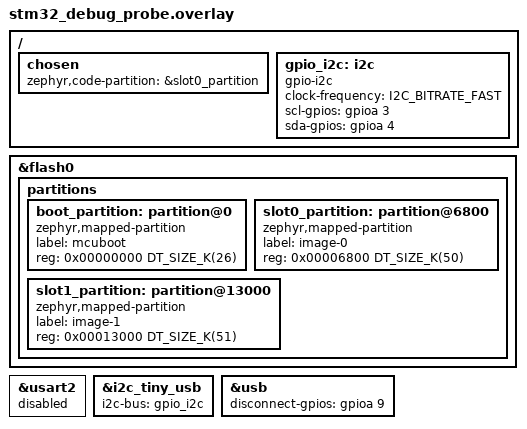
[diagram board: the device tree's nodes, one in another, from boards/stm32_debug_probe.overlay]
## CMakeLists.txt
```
# SPDX-FileCopyrightText: 2026 Muhammad Waleed Badar
# SPDX-License-Identifier: Apache-2.0

cmake_minimum_required(VERSION 3.20.0)

# The board overlays select the bus of the i2c-tiny-usb node of app.overlay,
# which Zephyr only uses for boards without an overlay of their own. Sysbuild
# builds get the same overlays from sysbuild.cmake. Twister passes the board
# with its revision and qualifiers, e.g. stm32f3_disco@B/stm32f303xc.
if(BOARD AND NOT DTC_OVERLAY_FILE)
  string(REGEX MATCH "^[^@/]+" board_name ${BOARD})
  set(board_overlay ${CMAKE_CURRENT_SOURCE_DIR}/boards/${board_name}.overlay)
  if(EXISTS ${board_overlay})
    set(DTC_OVERLAY_FILE "${CMAKE_CURRENT_SOURCE_DIR}/app.overlay;${board_overlay}")
  endif()
endif()

find_package(Zephyr REQUIRED HINTS $ENV{ZEPHYR_BASE})
project(i2c_tiny_usb_bridge)

target_sources(app PRIVATE src/main.c)
target_sources_ifdef(CONFIG_APP_USBD_WINUSB app PRIVATE src/msosv2.c)
target_sources_ifdef(CONFIG_APP_DFU app PRIVATE src/dfu.c)

if(CONFIG_APP_DFU)
  math(EXPR usbd_vid "${CONFIG_APP_USBD_VID}")
  math(EXPR usbd_pid "${CONFIG_APP_USBD_PID}")
endif()

if(CONFIG_APP_DFU AND usbd_vid EQUAL 1027 AND usbd_pid EQUAL 50737) # 0403:c631
  message(WARNING "The Linux i2c-tiny-usb driver binds to all interfaces of the USB IDs "
    "of the original i2c-tiny-usb adapter and also creates an I2C adapter for the DFU "
    "interface. Use other USB IDs for DFU support.")
endif()
```

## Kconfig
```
# SPDX-FileCopyrightText: 2026 Muhammad Waleed Badar
# SPDX-FileCopyrightText: Copyright (c) 2024-2026 Henrik Brix Andersen <henrik@brixandersen.dk>
# SPDX-License-Identifier: Apache-2.0

mainmenu "i2c-tiny-usb bridge"

menu "i2c-tiny-usb bridge"

module = APP
module-str = i2c-tiny-usb bridge
source "subsys/logging/Kconfig.template.log_config"

config APP_BOOT_BANNER
	bool "Boot banner"
	default y if BOOT_BANNER
	select PRINTK
	help
	  Print the firmware version during boot up.

config APP_USBD_MANUFACTURER
	string "USB device manufacturer string"
	default "zephyr-i2c-tiny-usb-bridge"

config APP_USBD_PRODUCT
	string "USB device product string"
	default "i2c-tiny-usb bridge"

config APP_USBD_VID
	hex "USB vendor ID"
	default 0x1209
	help
	  Defaults to the pid.codes test IDs 0x1209:0x0001, which are only
	  meant for testing and private use. Set your own IDs before
	  distributing a device: open source projects can get a product ID
	  under the vendor ID 0x1209 from pid.codes. The udev rules in the
	  repository bind the Linux i2c-tiny-usb driver to the IDs.

config APP_USBD_PID
	hex "USB product ID"
	default 0x0001

config APP_USBD_SELF_POWERED
	bool "USB device is self-powered"

config APP_USBD_MAX_POWER
	int "USB device maximum power"
	default 50
	range 0 250
	help
	  Maximum current draw from the bus in milliampere (mA) divided by 2.
	  A value of 50 results in a maximum current draw value of 100 mA.

config APP_USBD_WINUSB
	bool "Microsoft OS 2.0 descriptors for WinUSB"
	default y
	help
	  Report Microsoft OS 2.0 descriptors, so that Windows 8.1 and newer
	  install the WinUSB driver automatically. libusb based tools can then
	  access the device without a driver installation.

config APP_USBD_WINUSB_VENDOR_CODE
	hex "Microsoft OS 2.0 descriptor vendor code"
	default 0x20
	range 0x08 0xff
	depends on APP_USBD_WINUSB
	help
	  bRequest of the vendor request that reads the Microsoft OS 2.0
	  descriptor set. It must not collide with the i2c-tiny-usb commands
	  0 to 7.

menuconfig APP_DFU
	bool "USB Device Firmware Upgrade (DFU) support"
	default y
	depends on BOOTLOADER_MCUBOOT
	depends on $(dt_nodelabel_enabled,slot1_partition)
	select FLASH
	select FLASH_MAP
	select STREAM_FLASH
	select IMG_MANAGER
	select IMG_ERASE_PROGRESSIVELY
	select USBD_DFU
	select USBD_DFU_FLASH
	select REBOOT
	help
	  Add a DFU runtime interface. dfu-util switches the device into DFU
	  mode, downloads a signed image into the slot-1 partition, and the
	  device reboots into MCUboot, which swaps the images.

if APP_DFU

configdefault USBD_DFU_FLASH_SLOT0
	default n

configdefault USBD_DFU_FLASH_SLOT1
	default y

config APP_USBD_DFU_VID
	hex "USB vendor ID in DFU mode"
	default APP_USBD_VID

config APP_USBD_DFU_PID
	hex "USB product ID in DFU mode"
	default APP_USBD_PID

config APP_DFU_REBOOT_DELAY
	int "Reboot delay"
	default 100
	range 0 60000
	help
	  Delay in milliseconds between the completion of a DFU download and
	  the reboot into MCUboot.

endif # APP_DFU

endmenu

source "Kconfig.zephyr"
```

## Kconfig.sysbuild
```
# SPDX-FileCopyrightText: 2026 Muhammad Waleed Badar
# SPDX-FileCopyrightText: Copyright (c) 2024-2026 Henrik Brix Andersen <henrik@brixandersen.dk>
# SPDX-License-Identifier: Apache-2.0

# MCUboot with signature checking does not fit next to two image slots in the
# 128 KiB flash and 20 KiB RAM of the STM32F103. Images are still verified
# against their SHA-256 hash.
choice BOOT_SIGNATURE_TYPE
	default BOOT_SIGNATURE_TYPE_NONE if BOARD = "stm32_debug_probe"
endchoice

source "share/sysbuild/Kconfig"
```

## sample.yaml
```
# SPDX-FileCopyrightText: 2026 Muhammad Waleed Badar
# SPDX-FileCopyrightText: Copyright (c) 2024-2026 Henrik Brix Andersen <henrik@brixandersen.dk>
# SPDX-License-Identifier: Apache-2.0

sample:
  description: i2c-tiny-usb compatible USB to I2C bridge firmware
  name: i2c-tiny-usb bridge
common:
  tags:
    - i2c
    - usb
  depends_on:
    - usbd
tests:
  app.i2c_tiny_usb:
    platform_allow:
      - stm32f3_disco
    integration_platforms:
      - stm32f3_disco
  app.i2c_tiny_usb.debug:
    platform_allow:
      - stm32f3_disco
    integration_platforms:
      - stm32f3_disco
    extra_args:
      - FILE_SUFFIX=debug
    harness: console
    harness_config:
      type: one_line
      regex:
        - "i2c-tiny-usb bridge ready"
  app.i2c_tiny_usb.arduino:
    filter: dt_nodelabel_enabled("arduino_i2c") and dt_nodelabel_enabled("zephyr_udc0")
    platform_allow:
      - frdm_k64f
      - nrf52840dk/nrf52840
      - nucleo_f413zh
    integration_platforms:
      - frdm_k64f
      - nrf52840dk/nrf52840
      - nucleo_f413zh
    extra_args:
      - EXTRA_DTC_OVERLAY_FILE=overlays/arduino_i2c.overlay
  app.i2c_tiny_usb.dfu:
    sysbuild: true
    platform_allow:
      - stm32f3_disco
    integration_platforms:
      - stm32f3_disco
  app.i2c_tiny_usb.hil:
    # Runs on a bridge attached to the host running twister
    platform_allow:
      - stm32f3_disco
    extra_args:
      - FILE_SUFFIX=debug
    harness: pytest
    harness_config:
      fixture: i2c_tiny_usb_host
      pytest_root:
        - "pytest/test_bridge.py"
      pytest_args:
        # LSM303DLHC magnetometer identification registers, revision B
        - "--target=0x1e:0x0a:0x48"
        - "--target=0x1e:0x0b:0x34"
        - "--target=0x1e:0x0c:0x33"
        - "--absent=0x10"
```

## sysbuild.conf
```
# SPDX-FileCopyrightText: 2026 Muhammad Waleed Badar
# SPDX-License-Identifier: Apache-2.0

# Used with --sysbuild: MCUboot with USB DFU support in the application
SB_CONFIG_BOOTLOADER_MCUBOOT=y
```

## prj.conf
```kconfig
CONFIG_USB_DEVICE_STACK_NEXT=y
CONFIG_I2C=y

# Release configuration, see prj_debug.conf for logging
CONFIG_LOG=n
CONFIG_BOOT_BANNER=n
CONFIG_PRINTK=n
```

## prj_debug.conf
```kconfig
# SPDX-FileCopyrightText: 2026 Muhammad Waleed Badar
# SPDX-FileCopyrightText: Copyright (c) 2024-2026 Henrik Brix Andersen <henrik@brixandersen.dk>
# SPDX-License-Identifier: Apache-2.0

CONFIG_USB_DEVICE_STACK_NEXT=y
CONFIG_I2C=y

# Logging configuration
CONFIG_LOG=y
CONFIG_UDC_DRIVER_LOG_LEVEL_WRN=y
CONFIG_USBD_LOG_LEVEL_WRN=y
CONFIG_USBD_I2C_TINY_USB_LOG_LEVEL_DBG=y
CONFIG_APP_LOG_LEVEL_DBG=y
```

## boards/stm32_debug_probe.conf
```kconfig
CONFIG_SERIAL=n
CONFIG_I2C_GPIO=y
```

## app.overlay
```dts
/*
 * SPDX-FileCopyrightText: 2026 Muhammad Waleed Badar
 *
 * SPDX-License-Identifier: Apache-2.0
 */

/*
 * Bridges the zephyr_i2c bus by default, board and extra overlays select a
 * different bus through the i2c_tiny_usb label
 */
/ {
	i2c_tiny_usb: i2c-tiny-usb {
		compatible = "i2c-tiny-usb";
	};
};
```

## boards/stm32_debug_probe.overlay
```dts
/*
 * SPDX-FileCopyrightText: 2026 Muhammad Waleed Badar
 *
 * SPDX-License-Identifier: Apache-2.0
 */

#include <zephyr/dt-bindings/i2c/i2c.h>

/*
 * The bus is bit-banged on the J2 header, SCL on PA3 and SDA on PA4. PA3 and
 * PA4 are tied to PA5 and PA7 on the board, which are left as inputs.
 *
 * The STM32F1 has no pull-ups on open-drain outputs: the bus needs external
 * pull-ups to 3.3 V (4.7 kOhm), unless the target board provides them.
 */
/ {
	chosen {
		/delete-property/ zephyr,console;
		/delete-property/ zephyr,shell-uart;
		zephyr,code-partition = &slot0_partition;
	};

	gpio_i2c: i2c {
		compatible = "gpio-i2c";
		clock-frequency = <I2C_BITRATE_FAST>;
		scl-gpios = <&gpioa 3 GPIO_OPEN_DRAIN>;
		sda-gpios = <&gpioa 4 GPIO_OPEN_DRAIN>;
		#address-cells = <1>;
		#size-cells = <0>;
	};
};

/*
 * MCUboot flash layout for USB DFU. MCUboot without image signature checking
 * fits in 26 KiB. The secondary slot is one 1 KiB page larger than the
 * primary slot, as required by MCUboot's swap using offset mode.
 */
&flash0 {
	partitions {
		#address-cells = <1>;
		#size-cells = <1>;
		ranges;

		boot_partition: partition@0 {
			compatible = "zephyr,mapped-partition";
			label = "mcuboot";
			reg = <0x00000000 DT_SIZE_K(26)>;
		};

		slot0_partition: partition@6800 {
			compatible = "zephyr,mapped-partition";
			label = "image-0";
			reg = <0x00006800 DT_SIZE_K(50)>;
		};

		slot1_partition: partition@13000 {
			compatible = "zephyr,mapped-partition";
			label = "image-1";
			reg = <0x00013000 DT_SIZE_K(51)>;
		};
	};
};

/* PA3 is the USART2 RX pin, the console stays on RTT */
&usart2 {
	status = "disabled";
};

&i2c_tiny_usb {
	i2c-bus = <&gpio_i2c>;
};

&usb {
	disconnect-gpios = <&gpioa 9 GPIO_ACTIVE_HIGH>;
};
```

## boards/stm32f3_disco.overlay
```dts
/*
 * SPDX-FileCopyrightText: 2026 Muhammad Waleed Badar
 *
 * SPDX-License-Identifier: Apache-2.0
 */

/*
 * I2C1 on PB6 (SCL) and PB7 (SDA), shared with the on-board LSM303
 * accelerometer (0x19) and magnetometer (0x1e). The board enumerates through
 * the USB USER connector.
 */

&i2c_tiny_usb {
	i2c-bus = <&i2c1>;
};
```

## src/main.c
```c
/*
 * SPDX-FileCopyrightText: 2026 Muhammad Waleed Badar
 * SPDX-FileCopyrightText: Copyright (c) 2024-2026 Henrik Brix Andersen <henrik@brixandersen.dk>
 *
 * SPDX-License-Identifier: Apache-2.0
 */

#include <zephyr/app_version.h>
#include <zephyr/device.h>
#include <zephyr/sys/printk.h>
#include <zephyr/usb/usbd.h>

#include <zephyr/logging/log.h>
LOG_MODULE_REGISTER(main, CONFIG_APP_LOG_LEVEL);

#include "bridge.h"

BUILD_ASSERT(DT_HAS_COMPAT_STATUS_OKAY(i2c_tiny_usb),
	     "Add an i2c-tiny-usb devicetree node selecting the I2C bus to bridge");

#if defined(APP_BUILD_VERSION) && !IS_EMPTY(APP_BUILD_VERSION)
#define BANNER_VERSION APP_VERSION_STRING " (" STRINGIFY(APP_BUILD_VERSION) ")"
#else
#define BANNER_VERSION APP_VERSION_STRING
#endif

/* The Linux i2c-tiny-usb driver reports bcdDevice as the firmware version */
#define BRIDGE_BCD_DEVICE                                                                  \
	(USB_DEC_TO_BCD(APP_VERSION_MAJOR) << 8 | USB_DEC_TO_BCD(APP_VERSION_MINOR))

USBD_DEVICE_DEFINE(bridge_usbd, DEVICE_DT_GET(DT_NODELABEL(zephyr_udc0)), CONFIG_APP_USBD_VID,
		   CONFIG_APP_USBD_PID);

USBD_DESC_LANG_DEFINE(bridge_lang);
USBD_DESC_MANUFACTURER_DEFINE(bridge_mfr, CONFIG_APP_USBD_MANUFACTURER);
USBD_DESC_PRODUCT_DEFINE(bridge_product, CONFIG_APP_USBD_PRODUCT);
#ifdef CONFIG_HWINFO_HAS_DRIVER
/* Unique per device, lets the host tell several bridges apart */
USBD_DESC_SERIAL_NUMBER_DEFINE(bridge_sn);
#endif
USBD_DESC_CONFIG_DEFINE(fs_cfg_desc, "FS Configuration");
USBD_DESC_CONFIG_DEFINE(hs_cfg_desc, "HS Configuration");

#define BRIDGE_CFG_ATTRIB (IS_ENABLED(CONFIG_APP_USBD_SELF_POWERED) ? USB_SCD_SELF_POWERED : 0)

USBD_CONFIGURATION_DEFINE(fs_config, BRIDGE_CFG_ATTRIB, CONFIG_APP_USBD_MAX_POWER, &fs_cfg_desc);
USBD_CONFIGURATION_DEFINE(hs_config, BRIDGE_CFG_ATTRIB, CONFIG_APP_USBD_MAX_POWER, &hs_cfg_desc);

static void msg_cb(struct usbd_context *const usbd_ctx, const struct usbd_msg *const msg)
{
	LOG_INF("USBD message: %s", usbd_msg_type_string(msg->type));

	if (IS_ENABLED(CONFIG_APP_DFU) && msg->type == USBD_MSG_DFU_APP_DETACH) {
		bridge_dfu_switch(usbd_ctx);
		return;
	}

	if (!usbd_can_detect_vbus(usbd_ctx)) {
		return;
	}

	if (msg->type == USBD_MSG_VBUS_READY && usbd_enable(usbd_ctx) != 0) {
		LOG_ERR("Failed to enable device support");
	}

	if (msg->type == USBD_MSG_VBUS_REMOVED && usbd_disable(usbd_ctx) != 0) {
		LOG_ERR("Failed to disable device support");
	}
}

static int add_configuration(const enum usbd_speed speed, struct usbd_config_node *const cfg)
{
	int err;

	err = usbd_add_configuration(&bridge_usbd, speed, cfg);
	if (err != 0) {
		return err;
	}

	/*
	 * The Linux driver sends its commands to interface 0, so the
	 * i2c-tiny-usb interface is registered first.
	 */
	err = usbd_register_class(&bridge_usbd, "i2c_tiny_usb", speed, 1);
	if (err != 0) {
		return err;
	}

	if (IS_ENABLED(CONFIG_APP_DFU)) {
		err = usbd_register_class(&bridge_usbd, "dfu_runtime", speed, 1);
		if (err != 0) {
			return err;
		}
	}

	usbd_device_set_code_triple(&bridge_usbd, speed, 0, 0, 0);

	return 0;
}

int bridge_add_descriptors(struct usbd_context *const uds_ctx)
{
	int err;

	err = usbd_add_descriptor(uds_ctx, &bridge_lang);
	if (err != 0) {
		return err;
	}

	err = usbd_add_descriptor(uds_ctx, &bridge_mfr);
	if (err != 0) {
		return err;
	}

	err = usbd_add_descriptor(uds_ctx, &bridge_product);
	if (err != 0) {
		return err;
	}

#ifdef CONFIG_HWINFO_HAS_DRIVER
	err = usbd_add_descriptor(uds_ctx, &bridge_sn);
	if (err != 0) {
		return err;
	}
#endif

	if (IS_ENABLED(CONFIG_APP_USBD_WINUSB)) {
		err = bridge_msosv2_add(uds_ctx);
		if (err != 0) {
			return err;
		}
	}

	return usbd_device_set_bcd_device(uds_ctx, BRIDGE_BCD_DEVICE);
}

static int setup_device(void)
{
	int err;

	err = bridge_add_descriptors(&bridge_usbd);
	if (err != 0) {
		return err;
	}

	if (USBD_SUPPORTS_HIGH_SPEED && usbd_caps_speed(&bridge_usbd) == USBD_SPEED_HS) {
		err = add_configuration(USBD_SPEED_HS, &hs_config);
		if (err != 0) {
			return err;
		}
	}

	err = add_configuration(USBD_SPEED_FS, &fs_config);
	if (err != 0) {
		return err;
	}

	return usbd_msg_register_cb(&bridge_usbd, msg_cb);
}

int main(void)
{
	int err;

#ifdef CONFIG_APP_BOOT_BANNER
	printk("*** i2c-tiny-usb bridge " BANNER_VERSION " ***\n");
#endif

	err = setup_device();
	if (err != 0) {
		LOG_ERR("Failed to set up USB device (%d)", err);
		return err;
	}

	err = usbd_init(&bridge_usbd);
	if (err != 0) {
		LOG_ERR("Failed to initialize device support (%d)", err);
		return err;
	}

	if (!usbd_can_detect_vbus(&bridge_usbd)) {
		err = usbd_enable(&bridge_usbd);
		if (err != 0) {
			LOG_ERR("Failed to enable device support (%d)", err);
			return err;
		}
	}

	if (IS_ENABLED(CONFIG_APP_DFU)) {
		bridge_dfu_confirm();
	}

	LOG_INF("i2c-tiny-usb bridge ready");

	return 0;
}
```

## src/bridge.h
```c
/*
 * SPDX-FileCopyrightText: 2026 Muhammad Waleed Badar
 *
 * SPDX-License-Identifier: Apache-2.0
 */

#ifndef BRIDGE_H
#define BRIDGE_H

#include <zephyr/usb/usbd.h>

/*
 * Add the device level descriptors shared by the runtime and the DFU mode
 * device contexts. Only one context is initialized at a time, the descriptor
 * nodes are released by usbd_shutdown().
 */
int bridge_add_descriptors(struct usbd_context *const uds_ctx);

/* Add the BOS descriptors and the Microsoft OS 2.0 descriptor set */
int bridge_msosv2_add(struct usbd_context *const uds_ctx);

/* Shut down the runtime device context and enumerate in DFU mode */
void bridge_dfu_switch(struct usbd_context *const runtime_ctx);

/* Confirm the running image, so that MCUboot does not revert it */
void bridge_dfu_confirm(void);

#endif /* BRIDGE_H */
```

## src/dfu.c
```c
/*
 * SPDX-FileCopyrightText: 2026 Muhammad Waleed Badar
 * SPDX-FileCopyrightText: Copyright (c) 2024 Nordic Semiconductor ASA
 *
 * SPDX-License-Identifier: Apache-2.0
 */

#include <zephyr/dfu/mcuboot.h>
#include <zephyr/kernel.h>
#include <zephyr/sys/reboot.h>
#include <zephyr/usb/usbd.h>

#include <zephyr/logging/log.h>
LOG_MODULE_REGISTER(dfu, CONFIG_APP_LOG_LEVEL);

#include "bridge.h"

/*
 * In DFU mode the device enumerates with a configuration that only has the
 * DFU interface of the built-in flash backend, serving the slot-1 partition.
 */
USBD_DEVICE_DEFINE(dfu_usbd, DEVICE_DT_GET(DT_NODELABEL(zephyr_udc0)), CONFIG_APP_USBD_DFU_VID,
		   CONFIG_APP_USBD_DFU_PID);

USBD_DESC_CONFIG_DEFINE(dfu_fs_cfg_desc, "DFU FS Configuration");
USBD_DESC_CONFIG_DEFINE(dfu_hs_cfg_desc, "DFU HS Configuration");

#define DFU_CFG_ATTRIB (IS_ENABLED(CONFIG_APP_USBD_SELF_POWERED) ? USB_SCD_SELF_POWERED : 0)

USBD_CONFIGURATION_DEFINE(dfu_fs_config, DFU_CFG_ATTRIB, CONFIG_APP_USBD_MAX_POWER,
			  &dfu_fs_cfg_desc);
USBD_CONFIGURATION_DEFINE(dfu_hs_config, DFU_CFG_ATTRIB, CONFIG_APP_USBD_MAX_POWER,
			  &dfu_hs_cfg_desc);

static void dfu_reboot(struct k_work *work)
{
	sys_reboot(SYS_REBOOT_COLD);
}

static K_WORK_DELAYABLE_DEFINE(dfu_reboot_work, dfu_reboot);

static void dfu_msg_cb(struct usbd_context *const usbd_ctx, const struct usbd_msg *const msg)
{
	int err;

	LOG_INF("DFU USBD message: %s", usbd_msg_type_string(msg->type));

	if (usbd_can_detect_vbus(usbd_ctx)) {
		if (msg->type == USBD_MSG_VBUS_READY && usbd_enable(usbd_ctx) != 0) {
			LOG_ERR("Failed to enable device support");
		}

		if (msg->type == USBD_MSG_VBUS_REMOVED && usbd_disable(usbd_ctx) != 0) {
			LOG_ERR("Failed to disable device support");
		}
	}

	if (msg->type == USBD_MSG_DFU_DOWNLOAD_COMPLETED) {
		/* MCUboot reverts the image unless it confirms itself after booting */
		err = boot_request_upgrade(BOOT_UPGRADE_TEST);
		if (err != 0) {
			LOG_ERR("Failed to request upgrade (%d)", err);
			return;
		}

		LOG_INF("Download completed, rebooting");
		k_work_schedule(&dfu_reboot_work, K_MSEC(CONFIG_APP_DFU_REBOOT_DELAY));
	}
}

static int dfu_add_configuration(const enum usbd_speed speed,
				 struct usbd_config_node *const cfg)
{
	int err;

	err = usbd_add_configuration(&dfu_usbd, speed, cfg);
	if (err != 0) {
		return err;
	}

	err = usbd_register_class(&dfu_usbd, "dfu_dfu", speed, 1);
	if (err != 0) {
		return err;
	}

	usbd_device_set_code_triple(&dfu_usbd, speed, 0, 0, 0);

	return 0;
}

static int dfu_setup_device(void)
{
	int err;

	err = bridge_add_descriptors(&dfu_usbd);
	if (err != 0) {
		return err;
	}

	if (USBD_SUPPORTS_HIGH_SPEED && usbd_caps_speed(&dfu_usbd) == USBD_SPEED_HS) {
		err = dfu_add_configuration(USBD_SPEED_HS, &dfu_hs_config);
		if (err != 0) {
			return err;
		}
	}

	err = dfu_add_configuration(USBD_SPEED_FS, &dfu_fs_config);
	if (err != 0) {
		return err;
	}

	err = usbd_msg_register_cb(&dfu_usbd, dfu_msg_cb);
	if (err != 0) {
		return err;
	}

	return usbd_init(&dfu_usbd);
}

void bridge_dfu_switch(struct usbd_context *const runtime_ctx)
{
	int err;

	LOG_INF("Detach, switching to DFU mode");

	(void)usbd_disable(runtime_ctx);
	(void)usbd_shutdown(runtime_ctx);

	err = dfu_setup_device();
	if (err != 0) {
		LOG_ERR("Failed to set up DFU mode (%d)", err);
		return;
	}

	if (!usbd_can_detect_vbus(&dfu_usbd)) {
		err = usbd_enable(&dfu_usbd);
		if (err != 0) {
			LOG_ERR("Failed to enable DFU mode (%d)", err);
		}
	}
}

void bridge_dfu_confirm(void)
{
	int err;

	if (boot_is_img_confirmed()) {
		return;
	}

	err = boot_write_img_confirmed();
	if (err != 0) {
		LOG_ERR("Failed to confirm image (%d)", err);
		return;
	}

	LOG_INF("Image confirmed");
}
```

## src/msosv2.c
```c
/*
 * SPDX-FileCopyrightText: 2026 Muhammad Waleed Badar
 * SPDX-FileCopyrightText: Copyright (c) 2016-2019 Intel Corporation
 * SPDX-FileCopyrightText: Copyright (c) 2023-2024 Nordic Semiconductor ASA
 *
 * SPDX-License-Identifier: Apache-2.0
 */

#include <zephyr/net_buf.h>
#include <zephyr/sys/byteorder.h>
#include <zephyr/sys/util.h>
#include <zephyr/usb/bos.h>
#include <zephyr/usb/msos_desc.h>
#include <zephyr/usb/usbd.h>

#include "bridge.h"

/*
 * Microsoft OS 2.0 descriptor set without function subsets, so that Windows
 * binds WinUSB to the whole device, in runtime and in DFU mode. See the
 * Microsoft OS 2.0 Descriptors Specification for reference.
 */
#define MSOSV2_OS_VERSION 0x06030000UL /* Windows 8.1 */

/* {5C0A3FB5-29BD-401A-AB9B-6D69EF4EF7B0} */
#define BRIDGE_DEVICE_INTERFACE_GUID                                                       \
	'{', 0x00, '5', 0x00, 'C', 0x00, '0', 0x00, 'A', 0x00, '3', 0x00, 'F', 0x00,         \
	'B', 0x00, '5', 0x00, '-', 0x00, '2', 0x00, '9', 0x00, 'B', 0x00, 'D', 0x00,         \
	'-', 0x00, '4', 0x00, '0', 0x00, '1', 0x00, 'A', 0x00, '-', 0x00, 'A', 0x00,         \
	'B', 0x00, '9', 0x00, 'B', 0x00, '-', 0x00, '6', 0x00, 'D', 0x00, '6', 0x00,         \
	'9', 0x00, 'E', 0x00, 'F', 0x00, '4', 0x00, 'E', 0x00, 'F', 0x00, '7', 0x00,         \
	'B', 0x00, '0', 0x00, '}', 0x00, 0x00, 0x00, 0x00, 0x00

struct msosv2_descriptor {
	struct msosv2_descriptor_set_header header;
	struct msosv2_compatible_id compatible_id;
	struct msosv2_guids_property guids_property;
} __packed;

static const struct msosv2_descriptor msosv2_desc = {
	.header = {
		.wLength = sys_cpu_to_le16(sizeof(struct msosv2_descriptor_set_header)),
		.wDescriptorType = sys_cpu_to_le16(MS_OS_20_SET_HEADER_DESCRIPTOR),
		.dwWindowsVersion = sys_cpu_to_le32(MSOSV2_OS_VERSION),
		.wTotalLength = sys_cpu_to_le16(sizeof(struct msosv2_descriptor)),
	},
	.compatible_id = {
		.wLength = sys_cpu_to_le16(sizeof(struct msosv2_compatible_id)),
		.wDescriptorType = sys_cpu_to_le16(MS_OS_20_FEATURE_COMPATIBLE_ID),
		.CompatibleID = {'W', 'I', 'N', 'U', 'S', 'B', 0x00, 0x00},
	},
	.guids_property = {
		.wLength = sys_cpu_to_le16(sizeof(struct msosv2_guids_property)),
		.wDescriptorType = sys_cpu_to_le16(MS_OS_20_FEATURE_REG_PROPERTY),
		.wPropertyDataType = sys_cpu_to_le16(MS_OS_20_PROPERTY_DATA_REG_MULTI_SZ),
		.wPropertyNameLength = sys_cpu_to_le16(42),
		.PropertyName = {DEVICE_INTERFACE_GUIDS_PROPERTY_NAME},
		.wPropertyDataLength = sys_cpu_to_le16(80),
		.bPropertyData = {BRIDGE_DEVICE_INTERFACE_GUID},
	},
};

struct bos_msosv2_descriptor {
	struct usb_bos_platform_descriptor platform;
	struct usb_bos_capability_msos cap;
} __packed;

static const struct bos_msosv2_descriptor bos_msosv2_desc = {
	.platform = {
		.bLength = sizeof(struct usb_bos_platform_descriptor) +
			   sizeof(struct usb_bos_capability_msos),
		.bDescriptorType = USB_DESC_DEVICE_CAPABILITY,
		.bDevCapabilityType = USB_BOS_CAPABILITY_PLATFORM,
		.bReserved = 0,
		/* D8DD60DF-4589-4CC7-9CD2-659D9E648A9F */
		.PlatformCapabilityUUID = {
			0xDF, 0x60, 0xDD, 0xD8,
			0x89, 0x45,
			0xC7, 0x4C,
			0x9C, 0xD2,
			0x65, 0x9D, 0x9E, 0x64, 0x8A, 0x9F,
		},
	},
	.cap = {
		.dwWindowsVersion = sys_cpu_to_le32(MSOSV2_OS_VERSION),
		.wMSOSDescriptorSetTotalLength = sys_cpu_to_le16(sizeof(msosv2_desc)),
		.bMS_VendorCode = CONFIG_APP_USBD_WINUSB_VENDOR_CODE,
		.bAltEnumCode = 0x00,
	},
};

static const struct usb_bos_capability_lpm bos_cap_lpm = {
	.bLength = sizeof(struct usb_bos_capability_lpm),
	.bDescriptorType = USB_DESC_DEVICE_CAPABILITY,
	.bDevCapabilityType = USB_BOS_CAPABILITY_EXTENSION,
	.bmAttributes = 0UL,
};

static struct net_buf *msosv2_to_host(const struct usbd_context *const uds_ctx,
				      const struct usb_setup_packet *const setup)
{
	struct net_buf *buf;
	uint16_t len;

	if (setup->wIndex != MS_OS_20_DESCRIPTOR_INDEX) {
		return NULL;
	}

	len = MIN(setup->wLength, sizeof(msosv2_desc));
	buf = usbd_ep_ctrl_data_in_alloc(uds_ctx, len);
	if (buf == NULL) {
		return NULL;
	}

	net_buf_add_mem(buf, &msosv2_desc, len);

	return buf;
}

USBD_DESC_BOS_DEFINE(bridge_bos_lpm, sizeof(bos_cap_lpm), &bos_cap_lpm);
USBD_DESC_BOS_VREQ_DEFINE(bridge_bos_msosv2, sizeof(bos_msosv2_desc), &bos_msosv2_desc,
			  CONFIG_APP_USBD_WINUSB_VENDOR_CODE, msosv2_to_host, NULL);

int bridge_msosv2_add(struct usbd_context *const uds_ctx)
{
	int err;

	/* The host only reads the BOS descriptor from USB 2.01 devices */
	err = usbd_device_set_bcd_usb(uds_ctx, USBD_SPEED_FS, USB_SRN_2_0_1);
	if (err != 0) {
		return err;
	}

	if (USBD_SUPPORTS_HIGH_SPEED && usbd_caps_speed(uds_ctx) == USBD_SPEED_HS) {
		err = usbd_device_set_bcd_usb(uds_ctx, USBD_SPEED_HS, USB_SRN_2_0_1);
		if (err != 0) {
			return err;
		}
	}

	err = usbd_add_descriptor(uds_ctx, &bridge_bos_lpm);
	if (err != 0) {
		return err;
	}

	return usbd_add_descriptor(uds_ctx, &bridge_bos_msosv2);
}
```
